# GD32H71x_72x register map
File version: 1.0
CPU: CM7 r1p2, little endian, MPU, FPU, 4 interrupt priority bits
Registers are 32-bit, read-write, reset 0x0 unless marked. A register's access mark holds for its fields unless they carry their own. Offsets are from the block's base; [hi:lo] are bit positions; {n}, {i} and the like mark numbered series.

## HDSL0 — HIPERFACE DSL encoder interface module
Base 0x4000D800
Same registers: HDSL1 0x40002C00
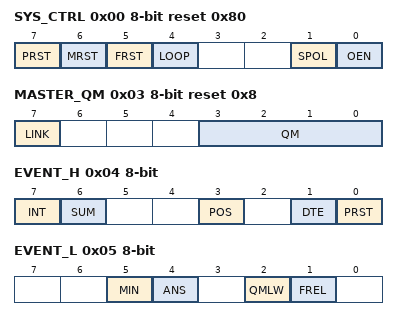
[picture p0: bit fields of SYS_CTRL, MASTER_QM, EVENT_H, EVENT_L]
0x00 SYS_CTRL 8-bit reset 0x80 — HDSL system control register
  [7] PRST — Protocol reset
  [6] MRST — Message reset
  [5] FRST — Pipeline FIFO reset
  [4] LOOP — Test drive interface
  [1] SPOL — Polarity of the synchronization pulse
  [0] OEN — Activation of the output
0x01 SYNC_CTRL 8-bit wo — HDSL synchronization control register
  [7:0] ES — External synchronization
0x03 MASTER_QM 8-bit ro reset 0x8 — HDSL quality monitoring register
  [7] LINK — DSL protocol connection status
  [3:0] QM — Quality monitoring bits
0x04 EVENT_H 8-bit access per field — HDSL high byte event register
  [7] INT ro — Interrupt status
  [6] SUM rw — Remote event monitoring
  [3] POS rw — Estimator turned on
  [1] DTE rw — Estimator deviation threshold error
  [0] PRST rw — Protocol reset warning
0x05 EVENT_L 8-bit — HDSL low byte event register
  [5] MIN — Message initialization
  [4] ANS — Erroneous answer to 'long message'
  [2] QMLW — Quality monitoring low-value warning
  [1] FREL — Channel free for 'long message'
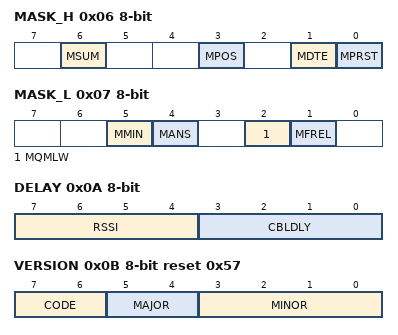
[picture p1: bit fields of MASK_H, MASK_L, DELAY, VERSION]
0x06 MASK_H 8-bit wo — HDSL high byte event mask register
  [6] MSUM — Mask for remote event monitoring
  [3] MPOS — Mask for fast position error
  [1] MDTE — Mask for estimator deviation threshold error warning
  [0] MPRST — Mask for protocol reset warning
0x07 MASK_L 8-bit wo — HDSL low byte event mask register
  [5] MMIN — Mask for message initialization confirmation
  [4] MANS — Mask for erroneous answer to 'long message'
  [2] MQMLW — Mask for low-quality monitoring value warning
  [1] MFREL — Mask for 'channel free for 'long message'
0x08 MASK_SUM 8-bit wo — HDSL summary mask register
  [7:0] MSUM — Mask for status summary bits
0x09 EDGES 8-bit ro — HDSL edge register
  [7:0] EDGES — Identification of edges in the cable signal
0x0A DELAY 8-bit ro — HDSL run time delay register
  [7:4] RSSI — Indication of the received signal strength
  [3:0] CBLDLY — 4-bit value for cable delay
0x0B VERSION 8-bit ro reset 0x57 — HDSL version register
  [7:6] CODE — Type of module
  [5:4] MAJOR — Major release number
  [3:0] MINOR — Minor release number
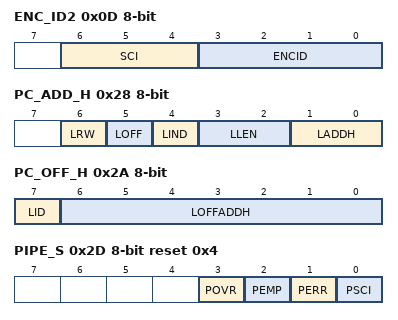
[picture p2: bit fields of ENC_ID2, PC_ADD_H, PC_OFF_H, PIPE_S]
0x0D ENC_ID2 8-bit ro — HDSL encoder ID 2 register
  [6:4] SCI — Indication of special characters
  [3:0] ENCID — Encoder designation code bit 19 to bit 16
0x0E ENC_ID1 8-bit ro — HDSL encoder ID 1 register
  [7:0] ENCID — Encoder designation code bit 15 to bit 8
0x0F ENC_ID0 8-bit ro — HDSL encoder ID 0 register
  [7:0] ENCID — Encoder designation code bit 7 to bit 0
0x10 POS4 8-bit ro — HDSL fast position byte 4 register
  [7:0] POS — Fast position, byte 4
0x11 POS3 8-bit ro — HDSL fast position byte 3 register
  [7:0] POS — Fast position, byte 3
0x12 POS2 8-bit ro — HDSL fast position byte 2 register
  [7:0] POS — Fast position, byte 2
0x13 POS1 8-bit ro — HDSL fast position byte 1 register
  [7:0] POS — Fast position, byte 1
0x14 POS0 8-bit ro — HDSL fast position byte 0 register
  [7:0] POS — Fast position, byte 0
0x15 VEL2 8-bit ro — HDSL speed byte 2 register
  [7:0] VEL — Speed, byte 2
0x16 VEL1 8-bit ro — HDSL speed byte 1 register
  [7:0] VEL — Speed, byte 1
0x17 VEL0 8-bit ro — HDSL speed byte 0 register
  [7:0] VEL — Speed, byte 0
0x18 MIR_SUM 8-bit ro — HDSL mirror status summary register
  [7:0] SUM — Status summary bit
{0x20+i} PC_BUFFER{i} 8-bit (i=0..7) — HDSL parameters channel buffer byte {i} register
  [7:0] PCBUF — Parameters Channel buffer
0x28 PC_ADD_H 8-bit access per field — HDSL high byte long message address register
  [6] LRW wo — Long message, read/write mode
  [5] LOFF rw — Long message addressing mode/long message error
  [4] LIND wo — Indirect addressing of long messages
  [3:2] LLEN wo — Data length of the 'long message'
  [1:0] LADDH wo — Long message address, bit 9 to bit 8
0x29 PC_ADD_L 8-bit wo — HDSL low byte long message address register
  [7:0] LADDL — Long message address, bit 7 to bit 0
0x2A PC_OFF_H 8-bit wo — HDSL high byte long message address offset register
  [7] LID — Long message identification.
  [6:0] LOFFADDH — Long message offset value, bit 14 to bit 8
0x2B PC_OFF_L 8-bit wo — HDSL low byte long message address offset register
  [7:0] LOFFADDH — Long message offset value, bit 7 to bit 0
0x2C PC_CTRL 8-bit wo — HDSL parameters channel control register
  [0] LSTA — Control of the long message start
0x2D PIPE_S 8-bit ro reset 0x4 — HDSL sensorhub channel status register
  [3] POVR — SensorHub Channel overflow
  [2] PEMP — The SensorHub channel buffer is empty
  [1] PERR — Coding error of the bits in the SensorHub Channel
  [0] PSCI — Indication for special characters in the SensorHub Channel
0x2E PIPE_D 8-bit ro — HDSL sensorhub channel data register
  [7:0] SCDATA — SensorHub Channel data
0x2F PC_DATA 8-bit ro — HDSL parameters channel short message mirror register
  [7:0] PCDATA — 'Short message' Mirror register data
0x38 ACC_ERR_CNT 8-bit — HDSL fast position error counter register
  [4:0] CNT — Position error count/threshold
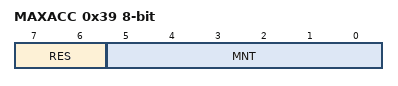
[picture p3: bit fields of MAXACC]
0x39 MAXACC 8-bit wo — HDSL fast position acceleration boundary register
  [7:6] RES — Resolution of fast position acceleration boundary
  [5:0] MNT — Mantissa of fast position acceleration boundary
0x3A MAXDEV_H 8-bit reset 0xFF — HDSL fast position estimator deviation high byte register
  [7:0] DEVH — Fast position estimator deviation high byte
0x3B MAXDEV_L 8-bit reset 0xFF — HDSL fast position estimator deviation low byte register
  [7:0] DEVL — Fast position estimator deviation low byte
0x3F DUMMY 8-bit ro — HDSL dummy register
  [7:0] DUMMY — Due to the transmission of the online-status
{0x60+i} MIR_ST{i} 8-bit (i=0..7) — HDSL mirror status {i} register
  [7:0] MIRST — Mirror status, byte {i}
